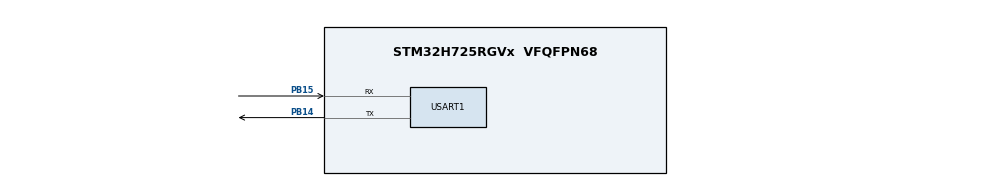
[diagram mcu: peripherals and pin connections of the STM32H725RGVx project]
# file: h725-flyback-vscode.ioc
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CORTEX_M7.default_mode_Activation=0
Dma.Request0=USART1_RX
Dma.Request1=USART1_TX
Dma.USART1_RX.0.Direction=DMA_PERIPH_TO_MEMORY
Dma.USART1_RX.0.EventEnable=DISABLE
Dma.USART1_RX.0.FIFOMode=DMA_FIFOMODE_DISABLE
Dma.USART1_RX.0.Instance=DMA1_Stream0
Dma.USART1_RX.0.MemDataAlignment=DMA_MDATAALIGN_BYTE
Dma.USART1_RX.0.MemInc=DMA_MINC_ENABLE
Dma.USART1_RX.0.Mode=DMA_NORMAL
Dma.USART1_RX.0.PeriphDataAlignment=DMA_PDATAALIGN_BYTE
Dma.USART1_RX.0.PeriphInc=DMA_PINC_DISABLE
Dma.USART1_RX.0.Polarity=HAL_DMAMUX_REQ_GEN_RISING
Dma.USART1_RX.0.Priority=DMA_PRIORITY_LOW
Dma.USART1_RX.0.RequestNumber=1
Dma.USART1_RX.0.SignalID=NONE
Dma.USART1_RX.0.SyncEnable=DISABLE
Dma.USART1_RX.0.SyncPolarity=HAL_DMAMUX_SYNC_NO_EVENT
Dma.USART1_RX.0.SyncRequestNumber=1
Dma.USART1_RX.0.SyncSignalID=NONE
Dma.USART1_TX.1.Direction=DMA_MEMORY_TO_PERIPH
Dma.USART1_TX.1.EventEnable=DISABLE
Dma.USART1_TX.1.FIFOMode=DMA_FIFOMODE_DISABLE
Dma.USART1_TX.1.Instance=DMA1_Stream1
Dma.USART1_TX.1.MemDataAlignment=DMA_MDATAALIGN_BYTE
Dma.USART1_TX.1.MemInc=DMA_MINC_ENABLE
Dma.USART1_TX.1.Mode=DMA_NORMAL
Dma.USART1_TX.1.PeriphDataAlignment=DMA_PDATAALIGN_BYTE
Dma.USART1_TX.1.PeriphInc=DMA_PINC_DISABLE
Dma.USART1_TX.1.Polarity=HAL_DMAMUX_REQ_GEN_RISING
Dma.USART1_TX.1.Priority=DMA_PRIORITY_LOW
Dma.USART1_TX.1.RequestNumber=1
Dma.USART1_TX.1.SignalID=NONE
Dma.USART1_TX.1.SyncEnable=DISABLE
Dma.USART1_TX.1.SyncPolarity=HAL_DMAMUX_SYNC_NO_EVENT
Dma.USART1_TX.1.SyncRequestNumber=1
Dma.USART1_TX.1.SyncSignalID=NONE
Mcu.Family=STM32H7
Mcu.Name=STM32H725RGVx
Mcu.Package=VFQFPN68
NVIC.DMA1_Stream0_IRQn=true\:0\:0\:false\:false\:true\:false\:true\:true
NVIC.DMA1_Stream1_IRQn=true\:0\:0\:false\:false\:true\:false\:true\:true
NVIC.PriorityGroup=NVIC_PRIORITYGROUP_4
NVIC.USART1_IRQn=true\:0\:0\:false\:false\:true\:false\:true\:true
PA13(JTMS/SWDIO).Mode=Serial_Wire
PA13(JTMS/SWDIO).Signal=DEBUG_JTMS-SWDIO
PA14(JTCK/SWCLK).Mode=Serial_Wire
PA14(JTCK/SWCLK).Signal=DEBUG_JTCK-SWCLK
PB14.Mode=Asynchronous
PB14.Signal=USART1_TX
PB15.Mode=Asynchronous
PB15.Signal=USART1_RX
ProjectManager.HeapSize=0x200
ProjectManager.StackSize=0x400
ProjectManager.TargetToolchain=CMake
RCC.ADCFreq_Value=129000000
RCC.APB1Freq_Value=137500000
RCC.APB2Freq_Value=137500000
RCC.APB3Freq_Value=137500000
RCC.APB4Freq_Value=137500000
RCC.CortexFreq_Value=550000000
RCC.D1PPRE=RCC_APB3_DIV2
RCC.D2PPRE1=RCC_APB1_DIV2
RCC.D2PPRE2=RCC_APB2_DIV2
RCC.D3PPRE=RCC_APB4_DIV2
RCC.DIVM1=4
RCC.DIVN1=34
RCC.DIVP1=1
RCC.HCLKFreq_Value=275000000
RCC.HPRE=RCC_HCLK_DIV2
RCC.PLLFRACN=3072
RCC.SYSCLKFreq_VALUE=550000000
RCC.SYSCLKSource=RCC_SYSCLKSOURCE_PLLCLK
RCC.USBFreq_Value=275000000
USART1.VirtualMode-Asynchronous=VM_ASYNC
VP_MEMORYMAP_VS_MEMORYMAP.Mode=CurAppReg
board=custom

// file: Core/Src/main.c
/* USER CODE BEGIN Header */
/**
  ******************************************************************************
  * @file           : main.c
  * @brief          : Main program body
  ******************************************************************************
  * @attention
  *
  * Copyright (c) 2025 STMicroelectronics.
  * All rights reserved.
  *
  * This software is licensed under terms that can be found in the LICENSE file
  * in the root directory of this software component.
  * If no LICENSE file comes with this software, it is provided AS-IS.
  *
  ******************************************************************************
  */
/* USER CODE END Header */
#include "main.h"
#include "dma.h"
#include "usart.h"
#include "gpio.h"

void SystemClock_Config(void);

int main(void)
{

  /* MCU Configuration--------------------------------------------------------*/

  /* Reset of all peripherals, Initializes the Flash interface and the Systick. */
  HAL_Init();

  /* Configure the system clock */
  SystemClock_Config();

  /* Initialize all configured peripherals */
  MX_GPIO_Init();
  MX_DMA_Init();
  MX_USART1_UART_Init();
  /* USER CODE BEGIN 2 */
  uint8_t msg[] = "DMA Test\n";
  HAL_StatusTypeDef status;
  /* USER CODE END 2 */

  /* Infinite loop */
  while (1)
  {

    /* USER CODE BEGIN 3 */
      status = HAL_UART_Transmit_DMA(&huart1, msg, sizeof(msg));
      HAL_Delay(100);
    /* USER CODE BEGIN 3 */
  }
  /* USER CODE END 3 */
}

void SystemClock_Config(void)
{
  RCC_OscInitTypeDef RCC_OscInitStruct = {0};
  RCC_ClkInitTypeDef RCC_ClkInitStruct = {0};

  /** Supply configuration update enable
  */
  HAL_PWREx_ConfigSupply(PWR_DIRECT_SMPS_SUPPLY);

  /** Configure the main internal regulator output voltage
  */
  __HAL_PWR_VOLTAGESCALING_CONFIG(PWR_REGULATOR_VOLTAGE_SCALE0);

  while(!__HAL_PWR_GET_FLAG(PWR_FLAG_VOSRDY)) {}

  /** Initializes the RCC Oscillators according to the specified parameters
  * in the RCC_OscInitTypeDef structure.
  */
  RCC_OscInitStruct.OscillatorType = RCC_OSCILLATORTYPE_HSI;
  RCC_OscInitStruct.HSIState = RCC_HSI_DIV1;
  RCC_OscInitStruct.HSICalibrationValue = 64;
  RCC_OscInitStruct.PLL.PLLState = RCC_PLL_ON;
  RCC_OscInitStruct.PLL.PLLSource = RCC_PLLSOURCE_HSI;
  RCC_OscInitStruct.PLL.PLLM = 4;
  RCC_OscInitStruct.PLL.PLLN = 34;
  RCC_OscInitStruct.PLL.PLLP = 1;
  RCC_OscInitStruct.PLL.PLLQ = 2;
  RCC_OscInitStruct.PLL.PLLR = 2;
  RCC_OscInitStruct.PLL.PLLRGE = RCC_PLL1VCIRANGE_3;
  RCC_OscInitStruct.PLL.PLLVCOSEL = RCC_PLL1VCOWIDE;
  RCC_OscInitStruct.PLL.PLLFRACN = 3072;
  if (HAL_RCC_OscConfig(&RCC_OscInitStruct) != HAL_OK)
  {
    Error_Handler();
  }

  /** Initializes the CPU, AHB and APB buses clocks
  */
  RCC_ClkInitStruct.ClockType = RCC_CLOCKTYPE_HCLK|RCC_CLOCKTYPE_SYSCLK
                              |RCC_CLOCKTYPE_PCLK1|RCC_CLOCKTYPE_PCLK2
                              |RCC_CLOCKTYPE_D3PCLK1|RCC_CLOCKTYPE_D1PCLK1;
  RCC_ClkInitStruct.SYSCLKSource = RCC_SYSCLKSOURCE_PLLCLK;
  RCC_ClkInitStruct.SYSCLKDivider = RCC_SYSCLK_DIV1;
  RCC_ClkInitStruct.AHBCLKDivider = RCC_HCLK_DIV2;
  RCC_ClkInitStruct.APB3CLKDivider = RCC_APB3_DIV2;
  RCC_ClkInitStruct.APB1CLKDivider = RCC_APB1_DIV2;
  RCC_ClkInitStruct.APB2CLKDivider = RCC_APB2_DIV2;
  RCC_ClkInitStruct.APB4CLKDivider = RCC_APB4_DIV2;

  if (HAL_RCC_ClockConfig(&RCC_ClkInitStruct, FLASH_LATENCY_3) != HAL_OK)
  {
    Error_Handler();
  }
}

void Error_Handler(void)
{
  __disable_irq();
  while (1)
  {
  }
}
